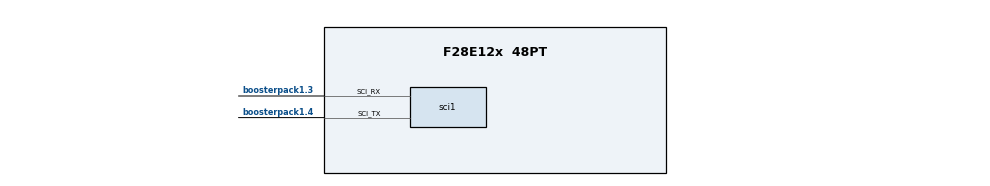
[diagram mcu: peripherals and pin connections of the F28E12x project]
/**
 * @cliArgs --board "/boards/LAUNCHXL_F28E12X" --device "F28E12x" --part "F28E12x_48PT" --package "48PT" --product "C2000WARE@6.00.00.00"
 * @versions {"tool":"1.23.999+220"}
 */

/**
 * Import the modules used in this configuration.
 */
const led       = scripting.addModule("/driverlib/board_components/led", {}, false);
const led1      = led.addInstance();
const cputimer  = scripting.addModule("/driverlib/cputimer.js", {}, false);
const cputimer1 = cputimer.addInstance();
const sci       = scripting.addModule("/driverlib/sci.js", {}, false);
const sci1      = sci.addInstance();

/**
 * Write custom configuration values to the imported modules.
 */
led1.$name     = "myBoardLED0";
led1.$hardware = system.deviceData.board.components.LED5;

cputimer1.$name                    = "myCPUTIMER0";
cputimer1.timerPeriod              = 200000000;
cputimer1.enableInterrupt          = true;
cputimer1.registerInterrupts       = true;
cputimer1.timerInt.enableInterrupt = true;

sci1.$name                 = "mySCIA";
sci1.baudRates             = 9600;
sci1.sci.$assign           = "SCIA";
sci1.sci.sci_rxPin.$assign = "boosterpack1.3";
sci1.sci.sci_txPin.$assign = "boosterpack1.4";
sci1.rxQual.$name          = "myGPIOQUAL0";
sci1.txQual.$name          = "myGPIOQUAL1";
